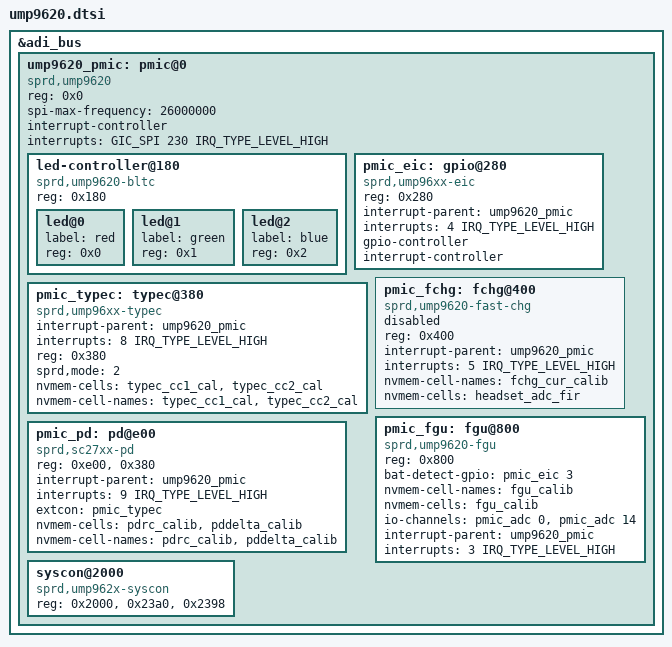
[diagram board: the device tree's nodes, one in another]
/*
 * UNISOC UMP9620 PMIC dts file
 *
 * Copyright (C) 2020, UNISOC Communications Inc.
 *
 * SPDX-License-Identifier: (GPL-2.0+ OR MIT)
*/

&adi_bus {
	#address-cells = <1>;
	#size-cells = <0>;

	ump9620_pmic: pmic@0 {
		compatible = "sprd,ump9620";
		reg = <0x0>;
		spi-max-frequency = <26000000>;
		interrupt-controller;
		#interrupt-cells = <2>;
		interrupts = <GIC_SPI 230 IRQ_TYPE_LEVEL_HIGH>;
		#address-cells = <1>;
		#size-cells = <0>;

		led-controller@180 {
			compatible = "sprd,ump9620-bltc", "sprd,sc27xx-bltc";
			#address-cells = <1>;
			#size-cells = <0>;
			reg = <0x180>;

			led@0 {
				label = "red";
				reg = <0x0>;
			};

			led@1 {
				label = "green";
				reg = <0x1>;
			};

			led@2 {
				label = "blue";
				reg = <0x2>;
			};
		};

		pmic_eic: gpio@280 {
			compatible = "sprd,ump96xx-eic", "sprd,sc27xx-eic", "sprd,sc2731-eic";
			reg = <0x280>;
			interrupt-parent = <&ump9620_pmic>;
			interrupts = <4 IRQ_TYPE_LEVEL_HIGH>;
			gpio-controller;
			#gpio-cells = <2>;
			interrupt-controller;
			#interrupt-cells = <2>;
		};

		pmic_typec: typec@380 {
			compatible = "sprd,ump96xx-typec", "sprd,sc27xx-typec";
			interrupt-parent = <&ump9620_pmic>;
			interrupts = <8 IRQ_TYPE_LEVEL_HIGH>;
			reg = <0x380>;
			sprd,mode = <2>;
			nvmem-cells = <&typec_cc1_cal>, <&typec_cc2_cal>;
			nvmem-cell-names = "typec_cc1_cal", "typec_cc2_cal";
		};

		pmic_fchg: fchg@400 {
			compatible = "sprd,ump9620-fast-chg", "sprd,sc27xx-fast-chg";
			reg = <0x400>;
			interrupt-parent = <&ump9620_pmic>;
			interrupts = <5 IRQ_TYPE_LEVEL_HIGH>;
			nvmem-cell-names = "fchg_cur_calib";
			nvmem-cells = <&headset_adc_fir>;
			status = "disabled";
		};

		pmic_fgu: fgu@800 {
			compatible = "sprd,ump9620-fgu", "sprd,sc27xx-fgu";
			reg = <0x800>;
			bat-detect-gpio = <&pmic_eic 3 GPIO_ACTIVE_HIGH>;
			nvmem-cell-names = "fgu_calib";
			nvmem-cells = <&fgu_calib>;
			io-channels = <&pmic_adc 0>, <&pmic_adc 14>;
			io-channel-names = "bat-temp", "charge-vol";
			interrupt-parent = <&ump9620_pmic>;
			interrupts = <3 IRQ_TYPE_LEVEL_HIGH>;
		};

		pmic_pd: pd@e00 {
			compatible = "sprd,sc27xx-pd", "sprd,ump9620-pd";
			reg = <0xe00>, <0x380>;
			interrupt-parent = <&ump9620_pmic>;
			interrupts = <9 IRQ_TYPE_LEVEL_HIGH>;
			extcon = <&pmic_typec>;
			nvmem-cells = <&pdrc_calib>, <&pddelta_calib>;
			nvmem-cell-names = "pdrc_calib", "pddelta_calib";
		};

		syscon@2000 {
			compatible = "sprd,ump962x-syscon";
			reg = <0x2000>, <0x23a0>, <0x2398>;
		};
	};

};

#include "adc.dtsi"
#include "efuse.dtsi"
#include "regulator.dtsi"
#include "audio-codec.dtsi"
